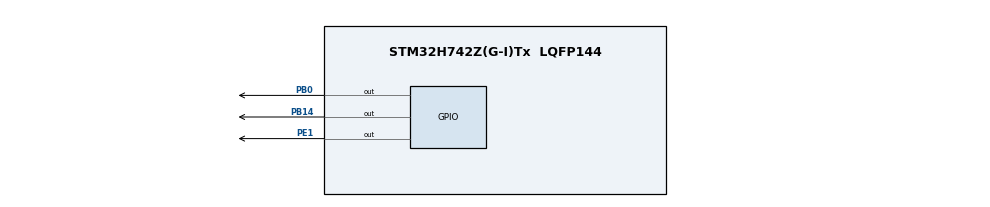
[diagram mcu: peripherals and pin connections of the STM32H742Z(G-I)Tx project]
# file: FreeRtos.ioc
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Mcu.Family=STM32H7
RCC.PLLSourceVirtual=RCC_PLLSOURCE_HSE
VP_SYS_VS_tim6.Mode=TIM6
RCC.CortexFreq_Value=75000000
FREERTOS.Tasks01=defaultTask,0,128,StartDefaultTask,Default,NULL,Dynamic,NULL,NULL
NVIC.TIM6_DAC_IRQn=true\:0\:0\:false\:false\:true\:false\:false\:true
PH0-OSC_IN\ (PH0).Signal=RCC_OSC_IN
PE1.GPIO_PuPd=GPIO_PULLDOWN
PH1-OSC_OUT\ (PH1).Signal=RCC_OSC_OUT
RCC.SYSCLKSource=RCC_SYSCLKSOURCE_PLLCLK
ProjectManager.StackSize=0x4000
ProjectManager.TargetToolchain=MDK-ARM V5.27
RCC.HCLKFreq_Value=75000000
RCC.DIVN1=150
RCC.USBFreq_Value=75000000
PE1.Signal=GPIO_Output
PB14.Signal=GPIO_Output
PH1-OSC_OUT\ (PH1).Mode=HSE-External-Oscillator
FREERTOS.configUSE_TIMERS=0
board=custom
RCC.DIVM1=25
RCC.APB2Freq_Value=75000000
RCC.ADCFreq_Value=50390625
VP_FREERTOS_VS_CMSIS_V1.Mode=CMSIS_V1
Mcu.Name=STM32H742Z(G-I)Tx
RCC.APB3Freq_Value=75000000
RCC.SYSCLKFreq_VALUE=75000000
Mcu.Package=LQFP144
PB14.GPIO_PuPd=GPIO_PULLDOWN
NVIC.TimeBase=TIM6_DAC_IRQn
NVIC.TimeBaseIP=TIM6
ProjectManager.HeapSize=0x2000
NVIC.PriorityGroup=NVIC_PRIORITYGROUP_4
RCC.APB4Freq_Value=75000000
RCC.APB1Freq_Value=75000000
PB0.Signal=GPIO_Output
PH0-OSC_IN\ (PH0).Mode=HSE-External-Oscillator
PB0.GPIO_PuPd=GPIO_PULLDOWN

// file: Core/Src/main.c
/* USER CODE BEGIN Header */
/**
  ******************************************************************************
  * @file           : main.c
  * @brief          : Main program body
  ******************************************************************************
  * @attention
  *
  * <h2><center>&copy; Copyright (c) 2021 STMicroelectronics.
  * All rights reserved.</center></h2>
  *
  * This software component is licensed by ST under Ultimate Liberty license
  * SLA0044, the "License"; You may not use this file except in compliance with
  * the License. You may obtain a copy of the License at:
  *                             www.st.com/SLA0044
  *
  ******************************************************************************
  */
/* USER CODE END Header */
#include "main.h"
#include "cmsis_os.h"

osThreadId defaultTaskHandle;
/* USER CODE BEGIN PV */

osThreadId Task1;

/* USER CODE END PV */

void SystemClock_Config(void);
static void MX_GPIO_Init(void);
void StartDefaultTask(void const * argument);

/* USER CODE BEGIN PFP */

void StartTask1(void const * argument);

/* USER CODE END PFP */

int main(void)
{

  /* MCU Configuration--------------------------------------------------------*/

  /* Reset of all peripherals, Initializes the Flash interface and the Systick. */
  HAL_Init();

  /* Configure the system clock */
  SystemClock_Config();

  /* Initialize all configured peripherals */
  MX_GPIO_Init();

  /* Create the thread(s) */
  /* definition and creation of defaultTask */
  osThreadDef(defaultTask, StartDefaultTask, osPriorityNormal, 0, 128);
  defaultTaskHandle = osThreadCreate(osThread(defaultTask), NULL);

  /* USER CODE BEGIN RTOS_THREADS */
  /* add threads, ... */

  osThreadDef(defaultTask1, StartTask1, osPriorityNormal, 0, 128);
  Task1 = osThreadCreate(osThread(defaultTask1), NULL);

  /* USER CODE END RTOS_THREADS */

  /* Start scheduler */
  osKernelStart();

  /* We should never get here as control is now taken by the scheduler */
  /* Infinite loop */
  while (1)
  {

  }
}

void SystemClock_Config(void)
{
  RCC_OscInitTypeDef RCC_OscInitStruct = {0};
  RCC_ClkInitTypeDef RCC_ClkInitStruct = {0};

  /** Supply configuration update enable
  */
  HAL_PWREx_ConfigSupply(PWR_LDO_SUPPLY);
  /** Configure the main internal regulator output voltage
  */
  __HAL_PWR_VOLTAGESCALING_CONFIG(PWR_REGULATOR_VOLTAGE_SCALE3);

  while(!__HAL_PWR_GET_FLAG(PWR_FLAG_VOSRDY)) {}
  /** Initializes the RCC Oscillators according to the specified parameters
  * in the RCC_OscInitTypeDef structure.
  */
  RCC_OscInitStruct.OscillatorType = RCC_OSCILLATORTYPE_HSE;
  RCC_OscInitStruct.HSEState = RCC_HSE_ON;
  RCC_OscInitStruct.PLL.PLLState = RCC_PLL_ON;
  RCC_OscInitStruct.PLL.PLLSource = RCC_PLLSOURCE_HSE;
  RCC_OscInitStruct.PLL.PLLM = 25;
  RCC_OscInitStruct.PLL.PLLN = 150;
  RCC_OscInitStruct.PLL.PLLP = 2;
  RCC_OscInitStruct.PLL.PLLQ = 2;
  RCC_OscInitStruct.PLL.PLLR = 2;
  RCC_OscInitStruct.PLL.PLLRGE = RCC_PLL1VCIRANGE_0;
  RCC_OscInitStruct.PLL.PLLVCOSEL = RCC_PLL1VCOMEDIUM;
  RCC_OscInitStruct.PLL.PLLFRACN = 0;
  if (HAL_RCC_OscConfig(&RCC_OscInitStruct) != HAL_OK)
  {
    Error_Handler();
  }
  /** Initializes the CPU, AHB and APB buses clocks
  */
  RCC_ClkInitStruct.ClockType = RCC_CLOCKTYPE_HCLK|RCC_CLOCKTYPE_SYSCLK
                              |RCC_CLOCKTYPE_PCLK1|RCC_CLOCKTYPE_PCLK2
                              |RCC_CLOCKTYPE_D3PCLK1|RCC_CLOCKTYPE_D1PCLK1;
  RCC_ClkInitStruct.SYSCLKSource = RCC_SYSCLKSOURCE_PLLCLK;
  RCC_ClkInitStruct.SYSCLKDivider = RCC_SYSCLK_DIV1;
  RCC_ClkInitStruct.AHBCLKDivider = RCC_HCLK_DIV1;
  RCC_ClkInitStruct.APB3CLKDivider = RCC_APB3_DIV1;
  RCC_ClkInitStruct.APB1CLKDivider = RCC_APB1_DIV1;
  RCC_ClkInitStruct.APB2CLKDivider = RCC_APB2_DIV1;
  RCC_ClkInitStruct.APB4CLKDivider = RCC_APB4_DIV1;

  if (HAL_RCC_ClockConfig(&RCC_ClkInitStruct, FLASH_LATENCY_1) != HAL_OK)
  {
    Error_Handler();
  }
}

static void MX_GPIO_Init(void)
{
  GPIO_InitTypeDef GPIO_InitStruct = {0};

  /* GPIO Ports Clock Enable */
  __HAL_RCC_GPIOH_CLK_ENABLE();
  __HAL_RCC_GPIOB_CLK_ENABLE();
  __HAL_RCC_GPIOE_CLK_ENABLE();

  /*Configure GPIO pin Output Level */
  HAL_GPIO_WritePin(GPIOB, GPIO_PIN_0|GPIO_PIN_14, GPIO_PIN_RESET);

  /*Configure GPIO pin Output Level */
  HAL_GPIO_WritePin(GPIOE, GPIO_PIN_1, GPIO_PIN_RESET);

  /*Configure GPIO pins : PB0 PB14 */
  GPIO_InitStruct.Pin = GPIO_PIN_0|GPIO_PIN_14;
  GPIO_InitStruct.Mode = GPIO_MODE_OUTPUT_PP;
  GPIO_InitStruct.Pull = GPIO_PULLDOWN;
  GPIO_InitStruct.Speed = GPIO_SPEED_FREQ_LOW;
  HAL_GPIO_Init(GPIOB, &GPIO_InitStruct);

  /*Configure GPIO pin : PE1 */
  GPIO_InitStruct.Pin = GPIO_PIN_1;
  GPIO_InitStruct.Mode = GPIO_MODE_OUTPUT_PP;
  GPIO_InitStruct.Pull = GPIO_PULLDOWN;
  GPIO_InitStruct.Speed = GPIO_SPEED_FREQ_LOW;
  HAL_GPIO_Init(GPIOE, &GPIO_InitStruct);

}

/* USER CODE BEGIN 4 */

void StartTask1(void const * argument)
{

  for(;;)
  {
    HAL_GPIO_TogglePin(GPIOE, GPIO_PIN_1);
    osDelay(250);
  }

}

/* USER CODE END 4 */

void StartDefaultTask(void const * argument)
{
  /* USER CODE BEGIN 5 */
  /* Infinite loop */
  for(;;)
  {
    HAL_GPIO_TogglePin(GPIOB, GPIO_PIN_0);
    HAL_GPIO_TogglePin(GPIOB, GPIO_PIN_14);
    osDelay(500);
  }
  /* USER CODE END 5 */
}

 /**
  * @brief  Period elapsed callback in non blocking mode
  * @note   This function is called  when TIM6 interrupt took place, inside
  * HAL_TIM_IRQHandler(). It makes a direct call to HAL_IncTick() to increment
  * a global variable "uwTick" used as application time base.
  * @param  htim : TIM handle
  * @retval None
  */
void HAL_TIM_PeriodElapsedCallback(TIM_HandleTypeDef *htim)
{
  if (htim->Instance == TIM6) {
    HAL_IncTick();
  }
}

void Error_Handler(void)
{
  __disable_irq();
  while (1)
  {
  }
}

/************************ (C) COPYRIGHT STMicroelectronics *****END OF FILE****/
